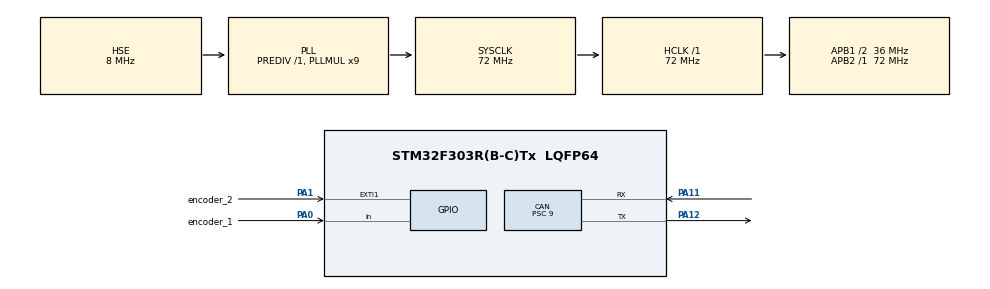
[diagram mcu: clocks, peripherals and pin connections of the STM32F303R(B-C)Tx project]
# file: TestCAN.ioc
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CAN.BS1=CAN_BS1_13TQ
CAN.BS2=CAN_BS2_2TQ
CAN.CalculateTimeQuantum=250.0
CAN.Mode=CAN_MODE_LOOPBACK
CAN.Prescaler=9
CAN.SJW=CAN_SJW_1TQ
Mcu.Family=STM32F3
Mcu.Name=STM32F303R(B-C)Tx
Mcu.Package=LQFP64
NVIC.EXTI1_IRQn=true\:0\:0\:false\:false\:true\:true\:true
NVIC.PriorityGroup=NVIC_PRIORITYGROUP_4
PA0.GPIO_Label=encoder_1
PA0.Signal=GPIO_Input
PA1.GPIO_Label=encoder_2
PA1.Signal=GPXTI1
PA11.Mode=Master
PA11.Signal=CAN_RX
PA12.Mode=Master
PA12.Signal=CAN_TX
PA13.Mode=Serial_Wire
PA13.Signal=SYS_JTMS-SWDIO
PA14.Mode=Serial_Wire
PA14.Signal=SYS_JTCK-SWCLK
PF0-OSC_IN.Mode=HSE-External-Oscillator
PF0-OSC_IN.Signal=RCC_OSC_IN
PF1-OSC_OUT.Mode=HSE-External-Oscillator
PF1-OSC_OUT.Signal=RCC_OSC_OUT
ProjectManager.HeapSize=0x200
ProjectManager.StackSize=0x400
ProjectManager.TargetToolchain=MDK-ARM V5.27
RCC.AHBFreq_Value=72000000
RCC.APB1CLKDivider=RCC_HCLK_DIV2
RCC.APB1Freq_Value=36000000
RCC.APB1TimFreq_Value=72000000
RCC.APB2Freq_Value=72000000
RCC.APB2TimFreq_Value=72000000
RCC.CortexFreq_Value=72000000
RCC.HCLKFreq_Value=72000000
RCC.HSE_VALUE=8000000
RCC.HSI_VALUE=8000000
RCC.LSE_VALUE=32768
RCC.PLLMUL=RCC_PLL_MUL9
RCC.PLLSourceVirtual=RCC_PLLSOURCE_HSE
RCC.SYSCLKFreq_VALUE=72000000
RCC.SYSCLKSourceVirtual=RCC_SYSCLKSOURCE_PLLCLK
RCC.USBFreq_Value=72000000
board=custom

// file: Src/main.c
/* USER CODE BEGIN Header */
/**
  ******************************************************************************
  * @file           : main.c
  * @brief          : Main program body
  ******************************************************************************
  * @attention
  *
  * <h2><center>&copy; Copyright (c) 2020 STMicroelectronics.
  * All rights reserved.</center></h2>
  *
  * This software component is licensed by ST under BSD 3-Clause license,
  * the "License"; You may not use this file except in compliance with the
  * License. You may obtain a copy of the License at:
  *                        opensource.org/licenses/BSD-3-Clause
  *
  ******************************************************************************
  */
/* USER CODE END Header */

#include "main.h"

/* USER CODE BEGIN Includes */
#include "variable.h"
/* USER CODE END Includes */

CAN_HandleTypeDef hcan;

void SystemClock_Config(void);
static void MX_GPIO_Init(void);
static void MX_CAN_Init(void);

/* USER CODE BEGIN 0 */

void HAL_GPIO_EXTI_Callback(uint16_t GPIO_Pin)
{
	if(GPIO_Pin == encoder_2_Pin)
	{
		if(HAL_GPIO_ReadPin(encoder_1_GPIO_Port,encoder_1_Pin))
		{
			rotary_value++;
		}
		else
		{
			rotary_value--;
		}
	}
}

/* USER CODE END 0 */

int main(void)
{

  /* MCU Configuration--------------------------------------------------------*/

  /* Reset of all peripherals, Initializes the Flash interface and the Systick. */
  HAL_Init();

  /* Configure the system clock */
  SystemClock_Config();

  /* Initialize all configured peripherals */
  MX_GPIO_Init();
  MX_CAN_Init();

  /* Infinite loop */
  while (1)
  {

  }
}

void SystemClock_Config(void)
{
  RCC_OscInitTypeDef RCC_OscInitStruct = {0};
  RCC_ClkInitTypeDef RCC_ClkInitStruct = {0};

  /** Initializes the CPU, AHB and APB busses clocks
  */
  RCC_OscInitStruct.OscillatorType = RCC_OSCILLATORTYPE_HSE;
  RCC_OscInitStruct.HSEState = RCC_HSE_ON;
  RCC_OscInitStruct.HSEPredivValue = RCC_HSE_PREDIV_DIV1;
  RCC_OscInitStruct.HSIState = RCC_HSI_ON;
  RCC_OscInitStruct.PLL.PLLState = RCC_PLL_ON;
  RCC_OscInitStruct.PLL.PLLSource = RCC_PLLSOURCE_HSE;
  RCC_OscInitStruct.PLL.PLLMUL = RCC_PLL_MUL9;
  if (HAL_RCC_OscConfig(&RCC_OscInitStruct) != HAL_OK)
  {
    Error_Handler();
  }
  /** Initializes the CPU, AHB and APB busses clocks
  */
  RCC_ClkInitStruct.ClockType = RCC_CLOCKTYPE_HCLK|RCC_CLOCKTYPE_SYSCLK
                              |RCC_CLOCKTYPE_PCLK1|RCC_CLOCKTYPE_PCLK2;
  RCC_ClkInitStruct.SYSCLKSource = RCC_SYSCLKSOURCE_PLLCLK;
  RCC_ClkInitStruct.AHBCLKDivider = RCC_SYSCLK_DIV1;
  RCC_ClkInitStruct.APB1CLKDivider = RCC_HCLK_DIV2;
  RCC_ClkInitStruct.APB2CLKDivider = RCC_HCLK_DIV1;

  if (HAL_RCC_ClockConfig(&RCC_ClkInitStruct, FLASH_LATENCY_2) != HAL_OK)
  {
    Error_Handler();
  }
}

static void MX_CAN_Init(void)
{

  hcan.Instance = CAN;
  hcan.Init.Prescaler = 9;
  hcan.Init.Mode = CAN_MODE_LOOPBACK;
  hcan.Init.SyncJumpWidth = CAN_SJW_1TQ;
  hcan.Init.TimeSeg1 = CAN_BS1_13TQ;
  hcan.Init.TimeSeg2 = CAN_BS2_2TQ;
  hcan.Init.TimeTriggeredMode = DISABLE;
  hcan.Init.AutoBusOff = DISABLE;
  hcan.Init.AutoWakeUp = DISABLE;
  hcan.Init.AutoRetransmission = DISABLE;
  hcan.Init.ReceiveFifoLocked = DISABLE;
  hcan.Init.TransmitFifoPriority = DISABLE;
  if (HAL_CAN_Init(&hcan) != HAL_OK)
  {
    Error_Handler();
  }

}

static void MX_GPIO_Init(void)
{
  GPIO_InitTypeDef GPIO_InitStruct = {0};

  /* GPIO Ports Clock Enable */
  __HAL_RCC_GPIOF_CLK_ENABLE();
  __HAL_RCC_GPIOA_CLK_ENABLE();

  /*Configure GPIO pin : encoder_1_Pin */
  GPIO_InitStruct.Pin = encoder_1_Pin;
  GPIO_InitStruct.Mode = GPIO_MODE_INPUT;
  GPIO_InitStruct.Pull = GPIO_NOPULL;
  HAL_GPIO_Init(encoder_1_GPIO_Port, &GPIO_InitStruct);

  /*Configure GPIO pin : encoder_2_Pin */
  GPIO_InitStruct.Pin = encoder_2_Pin;
  GPIO_InitStruct.Mode = GPIO_MODE_IT_RISING;
  GPIO_InitStruct.Pull = GPIO_NOPULL;
  HAL_GPIO_Init(encoder_2_GPIO_Port, &GPIO_InitStruct);

  /* EXTI interrupt init*/
  HAL_NVIC_SetPriority(EXTI1_IRQn, 0, 0);
  HAL_NVIC_EnableIRQ(EXTI1_IRQn);

}

void Error_Handler(void)
{
}

/************************ (C) COPYRIGHT STMicroelectronics *****END OF FILE****/
